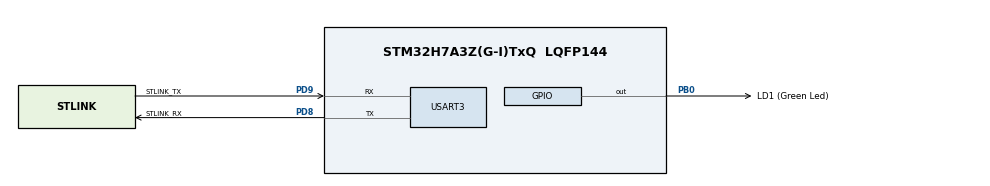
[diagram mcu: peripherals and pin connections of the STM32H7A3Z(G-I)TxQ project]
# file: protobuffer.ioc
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CORTEX_M7.default_mode_Activation=1
Mcu.Family=STM32H7
Mcu.Name=STM32H7A3Z(G-I)TxQ
Mcu.Package=LQFP144
NVIC.PriorityGroup=NVIC_PRIORITYGROUP_4
NVIC.USART3_IRQn=true\:0\:0\:false\:false\:true\:true\:true\:true
PB0.GPIO_Label=LD1 (Green Led)
PB0.Signal=GPIO_Output
PC14-OSC32_IN.GPIO_Label=OSC32_IN
PC14-OSC32_IN.Mode=LSE-External-Oscillator
PC14-OSC32_IN.Signal=RCC_OSC32_IN
PC15-OSC32_OUT.GPIO_Label=OSC32_OUT
PC15-OSC32_OUT.Mode=LSE-External-Oscillator
PC15-OSC32_OUT.Signal=RCC_OSC32_OUT
PD8.GPIO_Label=STLINK_RX
PD8.Mode=Asynchronous
PD8.Signal=USART3_TX
PD9.GPIO_Label=STLINK_TX
PD9.Mode=Asynchronous
PD9.Signal=USART3_RX
PH0-OSC_IN.GPIO_Label=PH0-MCU
PH0-OSC_IN.Mode=HSE-External-Oscillator
PH0-OSC_IN.Signal=RCC_OSC_IN
PH1-OSC_OUT.GPIO_Label=PH1-MCU
PH1-OSC_OUT.Mode=HSE-External-Oscillator
PH1-OSC_OUT.Signal=RCC_OSC_OUT
ProjectManager.HeapSize=0x200
ProjectManager.StackSize=0x400
ProjectManager.TargetToolchain=STM32CubeIDE
RCC.ADCFreq_Value=129000000
RCC.APB1Freq_Value=64000000
RCC.APB2Freq_Value=64000000
RCC.APB3Freq_Value=64000000
RCC.APB4Freq_Value=64000000
RCC.CortexFreq_Value=64000000
RCC.DIVM1=4
RCC.DIVM3=1
RCC.DIVN1=8
RCC.DIVN3=24
RCC.DIVQ1=4
RCC.HCLKFreq_Value=64000000
RCC.HSE_VALUE=8000000
RCC.PLLFRACN=0
RCC.PWR_Regulator_Voltage_Scale=PWR_REGULATOR_VOLTAGE_SCALE0
RCC.SYSCLKFreq_VALUE=64000000
RCC.SYSCLKSource=RCC_SYSCLKSOURCE_PLLCLK
RCC.SupplySource=PWR_DIRECT_SMPS_SUPPLY
RCC.USBCLockSelection=RCC_USBCLKSOURCE_HSI48
RCC.USBFreq_Value=48000000
USART3.VirtualMode-Asynchronous=VM_ASYNC
VP_MEMORYMAP_VS_MEMORYMAP.Mode=CurAppReg
board=NUCLEO-H7A3ZI-Q

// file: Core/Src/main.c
/* USER CODE BEGIN Header */
/**
 ******************************************************************************
 * @file           : main.c
 * @brief          : Main program body
 ******************************************************************************
 * @attention
 *
 * Copyright (c) 2025 STMicroelectronics.
 * All rights reserved.
 *
 * This software is licensed under terms that can be found in the LICENSE file
 * in the root directory of this software component.
 * If no LICENSE file comes with this software, it is provided AS-IS.
 *
 ******************************************************************************
 */
/* USER CODE END Header */
#include "main.h"
#include "memorymap.h"
#include "usart.h"
#include "gpio.h"

/* USER CODE BEGIN Includes */
#include <stdio.h>
#include <pb_encode.h>
#include <pb_decode.h>
#include "led_blink.pb.h"
#include "circularbuffer.h"
//#include "print.h"

/* USER CODE END Includes */

/* USER CODE BEGIN PTD */
#define MESSAGE_LENGTH 2
#define MESSAGE_ID 0x08

#define LED_ON 1
#define LED_OFF 0
/* USER CODE END PTD */

/* USER CODE BEGIN PV */

volatile uint8_t buffer[BUFFER_LEN];
static volatile uint8_t data[32] = { 0 };
static volatile uint8_t ch = 0;
static bool LedStat = 0;
static uint32_t DataCounter = 0;
static volatile uint8_t UartSign = 0;

/* USER CODE END PV */

void SystemClock_Config(void);
static void MPU_Config(void);

/* USER CODE BEGIN 0 */

/**
 * @brief function to use printf with uart
 * @param ch : character to transmit
 * @retval ch
 */
int __io_putchar(int ch) {
	HAL_UART_Transmit(&huart3, (uint8_t*) &ch, 1, 0xFFFF);
	return ch;
}
/**
 * @brief function for decode protocolbuffer message
 * @param None
 * @retval None
 */

LedStatus decode() {
	getdata_frombuffer((uint8_t*) data, MESSAGE_LENGTH);

	/* Allocate space for the decoded message. */
	LedStatus message = LedStatus_init_default;

	/* Create a stream that reads from the buffer. */
	pb_istream_t stream = pb_istream_from_buffer((uint8_t*) data,
			MESSAGE_LENGTH);

	LedStat = pb_decode(&stream, LedStatus_fields, &message);

	/*1 data take out from buffer*/
	DataCounter--;
	return message;
}
/**
 * @brief function for execute protocolbuffer message, Led on/off
 * @param None
 * @retval None
 */
void execute(LedStatus message) {
	if (LedStat != true) {
		return;
	}
	if (message.status == LED_ON) {
		//printf("led=1\r\n"); /*for debug*/
		HAL_GPIO_WritePin(LD1_GPIO_Port, LD1_Pin, GPIO_PIN_SET);
	} else if (message.status == LED_OFF) {
		//printf("led=0\r\n"); /*for debug*/
		HAL_GPIO_WritePin(LD1_GPIO_Port, LD1_Pin, GPIO_PIN_RESET);
	}
	/*invalid messages are ignored.*/
	/*invalid messages can not be here*/
}

/**
 * @brief function for handle uart interrupts
 * This function checks if the first byte is the start byte (0xFF), and the second byte is the message ID.
 * After reading the relevant data, it stores the processed information into the circular buffer.
 * @param UartSign: counts the relevant data
 * @retval None
 */
void HAL_UART_RxCpltCallback(UART_HandleTypeDef *huart) {
	if (huart->Instance != USART3) {
		return;
	}

	/*startbyte*/
	if (ch == 0xFF) {
		UartSign = 1;
	} else if (UartSign == 1 && ch == MESSAGE_ID) {
		data[UartSign - 1] = ch;
		UartSign = 2;
	} else if (UartSign > 1) {
		if (UartSign != MESSAGE_LENGTH) {
			data[UartSign - 1] = ch;
			UartSign++;
		} else {
			data[UartSign - 1] = ch;
			UartSign = 0;
			/*Until space is freed up for data*/
			while (!(writedata_tobuffer((uint8_t*) data, MESSAGE_LENGTH))) {
				/*if the buffer is full with unprocessed data, process*/
				execute(decode());
				printf("forcolt decode\r\n");
			}
			/*1 data arrived*/
			DataCounter++;
		}
	}
	HAL_UART_Receive_IT(&huart3, (uint8_t*) &ch, 1);

}
/* USER CODE END 0 */

int main(void) {

	/* MPU Configuration--------------------------------------------------------*/
	MPU_Config();

	/* MCU Configuration--------------------------------------------------------*/

	/* Reset of all peripherals, Initializes the Flash interface and the Systick. */
	HAL_Init();

	/* Configure the system clock */
	SystemClock_Config();

	/* Initialize all configured peripherals */
	MX_GPIO_Init();
	MX_USART3_UART_Init();
	/* USER CODE BEGIN 2 */

	/*test the Led1 peripheral*/
	HAL_GPIO_WritePin(LD1_GPIO_Port, LD1_Pin, GPIO_PIN_SET);
	HAL_Delay(1000);
	HAL_GPIO_WritePin(LD1_GPIO_Port, LD1_Pin, GPIO_PIN_RESET);
	HAL_Delay(1000);

	HAL_UART_Receive_IT(&huart3, (uint8_t*) &ch, 1);
	/* USER CODE END 2 */

	/* Infinite loop */
	/* USER CODE BEGIN WHILE */
	while (1) {
		printf("DataCounter: %ld\r\n", DataCounter); /*for testing*/
		if (DataCounter > 0) {
			execute(decode());
		}
		/* USER CODE END WHILE */

	}
}

void SystemClock_Config(void) {
	RCC_OscInitTypeDef RCC_OscInitStruct = { 0 };
	RCC_ClkInitTypeDef RCC_ClkInitStruct = { 0 };

	/*AXI clock gating */
	RCC->CKGAENR = 0xFFFFFFFF;

	/** Supply configuration update enable
	 */
	HAL_PWREx_ConfigSupply(PWR_DIRECT_SMPS_SUPPLY);

	/** Configure the main internal regulator output voltage
	 */
	__HAL_PWR_VOLTAGESCALING_CONFIG(PWR_REGULATOR_VOLTAGE_SCALE0);

	while (!__HAL_PWR_GET_FLAG(PWR_FLAG_VOSRDY)) {
	}

	/** Initializes the RCC Oscillators according to the specified parameters
	 * in the RCC_OscInitTypeDef structure.
	 */
	RCC_OscInitStruct.OscillatorType = RCC_OSCILLATORTYPE_HSI;
	RCC_OscInitStruct.HSIState = RCC_HSI_DIV1;
	RCC_OscInitStruct.HSICalibrationValue = 64;
	RCC_OscInitStruct.PLL.PLLState = RCC_PLL_ON;
	RCC_OscInitStruct.PLL.PLLSource = RCC_PLLSOURCE_HSI;
	RCC_OscInitStruct.PLL.PLLM = 4;
	RCC_OscInitStruct.PLL.PLLN = 8;
	RCC_OscInitStruct.PLL.PLLP = 2;
	RCC_OscInitStruct.PLL.PLLQ = 4;
	RCC_OscInitStruct.PLL.PLLR = 2;
	RCC_OscInitStruct.PLL.PLLRGE = RCC_PLL1VCIRANGE_3;
	RCC_OscInitStruct.PLL.PLLVCOSEL = RCC_PLL1VCOWIDE;
	RCC_OscInitStruct.PLL.PLLFRACN = 0;
	if (HAL_RCC_OscConfig(&RCC_OscInitStruct) != HAL_OK) {
		Error_Handler();
	}

	/** Initializes the CPU, AHB and APB buses clocks
	 */
	RCC_ClkInitStruct.ClockType = RCC_CLOCKTYPE_HCLK | RCC_CLOCKTYPE_SYSCLK
			| RCC_CLOCKTYPE_PCLK1 | RCC_CLOCKTYPE_PCLK2 | RCC_CLOCKTYPE_D3PCLK1
			| RCC_CLOCKTYPE_D1PCLK1;
	RCC_ClkInitStruct.SYSCLKSource = RCC_SYSCLKSOURCE_PLLCLK;
	RCC_ClkInitStruct.SYSCLKDivider = RCC_SYSCLK_DIV1;
	RCC_ClkInitStruct.AHBCLKDivider = RCC_HCLK_DIV1;
	RCC_ClkInitStruct.APB3CLKDivider = RCC_APB3_DIV1;
	RCC_ClkInitStruct.APB1CLKDivider = RCC_APB1_DIV1;
	RCC_ClkInitStruct.APB2CLKDivider = RCC_APB2_DIV1;
	RCC_ClkInitStruct.APB4CLKDivider = RCC_APB4_DIV1;

	if (HAL_RCC_ClockConfig(&RCC_ClkInitStruct, FLASH_LATENCY_1) != HAL_OK) {
		Error_Handler();
	}
}

/* MPU Configuration */

void MPU_Config(void) {
	MPU_Region_InitTypeDef MPU_InitStruct = { 0 };

	/* Disables the MPU */
	HAL_MPU_Disable();

	/** Initializes and configures the Region and the memory to be protected
	 */
	MPU_InitStruct.Enable = MPU_REGION_ENABLE;
	MPU_InitStruct.Number = MPU_REGION_NUMBER0;
	MPU_InitStruct.BaseAddress = 0x0;
	MPU_InitStruct.Size = MPU_REGION_SIZE_4GB;
	MPU_InitStruct.SubRegionDisable = 0x87;
	MPU_InitStruct.TypeExtField = MPU_TEX_LEVEL0;
	MPU_InitStruct.AccessPermission = MPU_REGION_NO_ACCESS;
	MPU_InitStruct.DisableExec = MPU_INSTRUCTION_ACCESS_DISABLE;
	MPU_InitStruct.IsShareable = MPU_ACCESS_SHAREABLE;
	MPU_InitStruct.IsCacheable = MPU_ACCESS_NOT_CACHEABLE;
	MPU_InitStruct.IsBufferable = MPU_ACCESS_NOT_BUFFERABLE;

	HAL_MPU_ConfigRegion(&MPU_InitStruct);
	/* Enables the MPU */
	HAL_MPU_Enable(MPU_PRIVILEGED_DEFAULT);

}

void Error_Handler(void) {
	__disable_irq();
	while (1) {
	}
}
